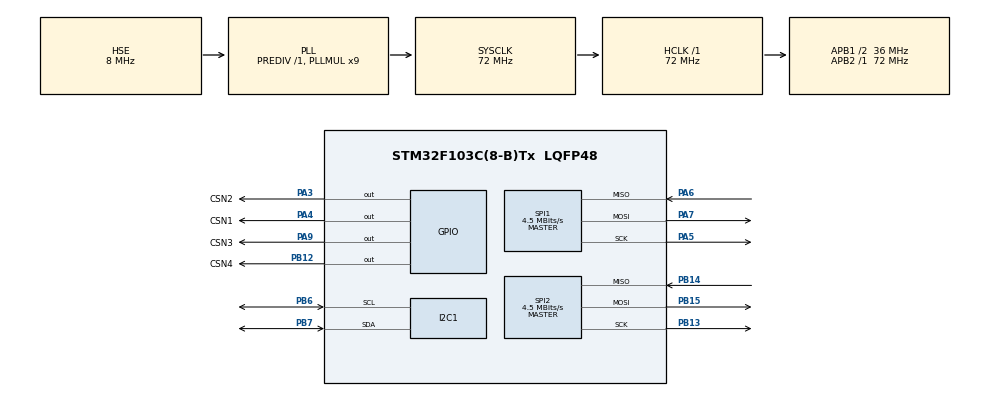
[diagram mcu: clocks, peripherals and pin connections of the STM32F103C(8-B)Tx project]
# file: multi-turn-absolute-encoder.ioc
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Mcu.Family=STM32F1
Mcu.Name=STM32F103C(8-B)Tx
Mcu.Package=LQFP48
NVIC.PriorityGroup=NVIC_PRIORITYGROUP_4
NVIC.TIM2_IRQn=true\:0\:0\:false\:false\:true\:true\:true\:true
PA13.Mode=Serial_Wire
PA13.Signal=SYS_JTMS-SWDIO
PA14.Mode=Serial_Wire
PA14.Signal=SYS_JTCK-SWCLK
PA3.GPIO_Label=CSN2
PA3.GPIO_Speed=GPIO_SPEED_FREQ_HIGH
PA3.PinState=GPIO_PIN_SET
PA3.Signal=GPIO_Output
PA4.GPIO_Label=CSN1
PA4.GPIO_Speed=GPIO_SPEED_FREQ_HIGH
PA4.PinState=GPIO_PIN_SET
PA4.Signal=GPIO_Output
PA5.Mode=Full_Duplex_Master
PA5.Signal=SPI1_SCK
PA6.Mode=Full_Duplex_Master
PA6.Signal=SPI1_MISO
PA7.Mode=Full_Duplex_Master
PA7.Signal=SPI1_MOSI
PA9.GPIO_Label=CSN3
PA9.GPIO_Speed=GPIO_SPEED_FREQ_HIGH
PA9.PinState=GPIO_PIN_SET
PA9.Signal=GPIO_Output
PB12.GPIO_Label=CSN4
PB12.GPIO_Speed=GPIO_SPEED_FREQ_HIGH
PB12.PinState=GPIO_PIN_SET
PB12.Signal=GPIO_Output
PB13.Mode=Full_Duplex_Master
PB13.Signal=SPI2_SCK
PB14.Mode=Full_Duplex_Master
PB14.Signal=SPI2_MISO
PB15.Mode=Full_Duplex_Master
PB15.Signal=SPI2_MOSI
PB6.Mode=I2C
PB6.Signal=I2C1_SCL
PB7.Mode=I2C
PB7.Signal=I2C1_SDA
PD0-OSC_IN.Mode=HSE-External-Oscillator
PD0-OSC_IN.Signal=RCC_OSC_IN
PD1-OSC_OUT.Mode=HSE-External-Oscillator
PD1-OSC_OUT.Signal=RCC_OSC_OUT
ProjectManager.HeapSize=0x200
ProjectManager.StackSize=0x400
ProjectManager.TargetToolchain=CMake
RCC.AHBFreq_Value=72000000
RCC.APB1CLKDivider=RCC_HCLK_DIV2
RCC.APB1Freq_Value=36000000
RCC.APB1TimFreq_Value=72000000
RCC.APB2Freq_Value=72000000
RCC.APB2TimFreq_Value=72000000
RCC.HCLKFreq_Value=72000000
RCC.PLLMUL=RCC_PLL_MUL9
RCC.PLLSourceVirtual=RCC_PLLSOURCE_HSE
RCC.SYSCLKFreq_VALUE=72000000
RCC.SYSCLKSource=RCC_SYSCLKSOURCE_PLLCLK
RCC.USBFreq_Value=72000000
SPI1.BaudRatePrescaler=SPI_BAUDRATEPRESCALER_16
SPI1.CLKPhase=SPI_PHASE_2EDGE
SPI1.CalculateBaudRate=4.5 MBits/s
SPI1.Direction=SPI_DIRECTION_2LINES
SPI1.Mode=SPI_MODE_MASTER
SPI1.VirtualType=VM_MASTER
SPI2.BaudRatePrescaler=SPI_BAUDRATEPRESCALER_8
SPI2.CLKPhase=SPI_PHASE_2EDGE
SPI2.CalculateBaudRate=4.5 MBits/s
SPI2.Direction=SPI_DIRECTION_2LINES
SPI2.Mode=SPI_MODE_MASTER
SPI2.VirtualType=VM_MASTER
TIM2.Period=1000-1
TIM2.Prescaler=72-1
VP_TIM2_VS_ClockSourceINT.Mode=Internal
board=custom

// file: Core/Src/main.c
/* USER CODE BEGIN Header */
/**
  ******************************************************************************
  * @file           : main.c
  * @brief          : Main program body
  ******************************************************************************
  * @attention
  *
  * Copyright (c) 2026 STMicroelectronics.
  * All rights reserved.
  *
  * This software is licensed under terms that can be found in the LICENSE file
  * in the root directory of this software component.
  * If no LICENSE file comes with this software, it is provided AS-IS.
  *
  ******************************************************************************
  */
/* USER CODE END Header */
#include "main.h"
#include "i2c.h"
#include "spi.h"
#include "tim.h"
#include "gpio.h"

/* USER CODE BEGIN Includes */
#include "app_entry.h" /* C entry point into the C++ application logic */
/* USER CODE END Includes */

/* USER CODE BEGIN PV */
/* set by the TIM2 update interrupt: the main loop takes one sample per tick.
 * All encoder/decoder state lives in App/ (app_entry.cpp), not here. */
static volatile uint32_t _sampleTick;
/* USER CODE END PV */

void SystemClock_Config(void);

int main(void)
{

  /* MCU Configuration--------------------------------------------------------*/

  /* Reset of all peripherals, Initializes the Flash interface and the Systick. */
  HAL_Init();

  /* Configure the system clock */
  SystemClock_Config();

  /* Initialize all configured peripherals */
  MX_GPIO_Init();
  MX_SPI1_Init();
  MX_I2C1_Init();
  MX_SPI2_Init();
  MX_TIM2_Init();
  /* USER CODE BEGIN 2 */
  if (!AppInit())
  {
    Error_Handler(); /* gear config invalid, see App/gear_config.h */
  }
  /* 1 kHz sample clock: TIM2 updates every 1 ms (PSC 71, ARR 999) and its
   * interrupt flags _sampleTick; the loop sleeps until each tick so sample
   * instants are anchored to the timer and cannot drift */
  HAL_TIM_Base_Start_IT(&htim2);
  /* USER CODE END 2 */

  /* Infinite loop */
  while (1)
  {

    /* USER CODE BEGIN 3 */
    /* sleep until the next TIM2 tick (spurious SysTick wakeups are harmless);
     * a slow iteration simply skips a sample and re-syncs on the next tick */
    while (!_sampleTick)
    {
      __WFI();
    }
    _sampleTick = 0u;

    AppProcessSample(); /* sample all four encoders, decode, publish to the
                         * I2C register map (App/app_entry.cpp) */
  }
  /* USER CODE END 3 */
}

void SystemClock_Config(void)
{
  RCC_OscInitTypeDef RCC_OscInitStruct = {0};
  RCC_ClkInitTypeDef RCC_ClkInitStruct = {0};

  /** Initializes the RCC Oscillators according to the specified parameters
  * in the RCC_OscInitTypeDef structure.
  */
  RCC_OscInitStruct.OscillatorType = RCC_OSCILLATORTYPE_HSE;
  RCC_OscInitStruct.HSEState = RCC_HSE_ON;
  RCC_OscInitStruct.HSEPredivValue = RCC_HSE_PREDIV_DIV1;
  RCC_OscInitStruct.HSIState = RCC_HSI_ON;
  RCC_OscInitStruct.PLL.PLLState = RCC_PLL_ON;
  RCC_OscInitStruct.PLL.PLLSource = RCC_PLLSOURCE_HSE;
  RCC_OscInitStruct.PLL.PLLMUL = RCC_PLL_MUL9;
  if (HAL_RCC_OscConfig(&RCC_OscInitStruct) != HAL_OK)
  {
    Error_Handler();
  }

  /** Initializes the CPU, AHB and APB buses clocks
  */
  RCC_ClkInitStruct.ClockType = RCC_CLOCKTYPE_HCLK|RCC_CLOCKTYPE_SYSCLK
                              |RCC_CLOCKTYPE_PCLK1|RCC_CLOCKTYPE_PCLK2;
  RCC_ClkInitStruct.SYSCLKSource = RCC_SYSCLKSOURCE_PLLCLK;
  RCC_ClkInitStruct.AHBCLKDivider = RCC_SYSCLK_DIV1;
  RCC_ClkInitStruct.APB1CLKDivider = RCC_HCLK_DIV2;
  RCC_ClkInitStruct.APB2CLKDivider = RCC_HCLK_DIV1;

  if (HAL_RCC_ClockConfig(&RCC_ClkInitStruct, FLASH_LATENCY_2) != HAL_OK)
  {
    Error_Handler();
  }
}

/* USER CODE BEGIN 4 */

/* TIM2 update event: just flags the loop - the sampling itself (SPI reads,
 * CRC, gear decode) runs in the main loop, not in interrupt context. */
void HAL_TIM_PeriodElapsedCallback(TIM_HandleTypeDef *htim)
{
  if (htim->Instance == TIM2)
  {
    _sampleTick = 1u;
  }
}

/* USER CODE END 4 */

void Error_Handler(void)
{
  __disable_irq();
  while (1)
  {
  }
}
